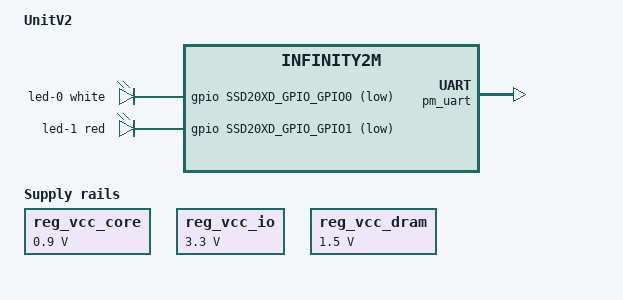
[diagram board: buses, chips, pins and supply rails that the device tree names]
// SPDX-License-Identifier: GPL-2.0-or-later
/*
 * Copyright (c) 2021 thingy.jp.
 * Author: Daniel Palmer <daniel@thingy.jp>
 */

/dts-v1/;
#include "mstar-infinity2m-ssd202d.dtsi"

#include <dt-bindings/gpio/gpio.h>
#include <dt-bindings/leds/common.h>

/ {
	model = "UnitV2";
	compatible = "m5stack,unitv2", "mstar,infinity2m";

	aliases {
		serial0 = &pm_uart;
	};

	chosen {
		stdout-path = "serial0:115200n8";
	};

	leds {
		compatible = "gpio-leds";
		led-0 {
			color = <LED_COLOR_ID_WHITE>;
			function = LED_FUNCTION_INDICATOR;
			gpios = <&gpio SSD20XD_GPIO_GPIO0 GPIO_ACTIVE_LOW>;
			linux,default-trigger = "activity";
		};
		led-1 {
			color = <LED_COLOR_ID_RED>;
			function = LED_FUNCTION_INDICATOR;
			gpios = <&gpio SSD20XD_GPIO_GPIO1 GPIO_ACTIVE_LOW>;
			linux,default-trigger = "heartbeat";
		};
	};

	reg_vcc_core: regulator-vcc-core {
		compatible = "regulator-fixed";
		regulator-name = "vcc_core";
		regulator-min-microvolt = <900000>;
		regulator-max-microvolt = <900000>;
		regulator-boot-on;
	};

	reg_vcc_io: regulator-vcc-io {
		compatible = "regulator-fixed";
		regulator-name = "vcc_io";
		regulator-min-microvolt = <3300000>;
		regulator-max-microvolt = <3300000>;
		regulator-boot-on;
	};

	reg_vcc_dram: regulator-vcc-dram {
		compatible = "regulator-fixed";
		regulator-name = "vcc_dram";
		regulator-min-microvolt = <1500000>;
		regulator-max-microvolt = <1500000>;
		regulator-boot-on;
	};
};

&pm_uart {
	status = "okay";
};
